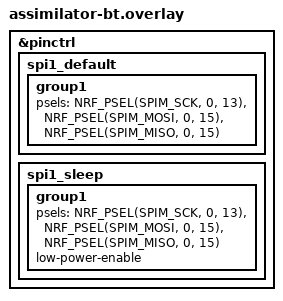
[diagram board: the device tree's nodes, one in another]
/*
 * Provide the SPI1 pinctrl nodes that the assimilator-bt board DTS references
 * but does not define itself (normally supplied by a keyboard shield overlay).
 */

&pinctrl {
    spi1_default: spi1_default {
        group1 {
            psels = <NRF_PSEL(SPIM_SCK, 0, 13)>,
                <NRF_PSEL(SPIM_MOSI, 0, 15)>,
                <NRF_PSEL(SPIM_MISO, 0, 15)>;
        };
    };

    spi1_sleep: spi1_sleep {
        group1 {
            psels = <NRF_PSEL(SPIM_SCK, 0, 13)>,
                <NRF_PSEL(SPIM_MOSI, 0, 15)>,
                <NRF_PSEL(SPIM_MISO, 0, 15)>;
            low-power-enable;
        };
    };
};
